# ESP32-S31 register map
Vendor: ESPRESSIF SYSTEMS (SHANGHAI) CO., LTD.; Series: ESP32 S-Series; File version: 1
CPU: RV32IMAFC r0p0, little endian, no MPU, FPU, 0 interrupt priority bits
Address unit: 32 bits
Registers are 32-bit, read-write, reset 0x0 unless marked. A register's access mark holds for its fields unless they carry their own. Offsets are from the block's base; [hi:lo] are bit positions; {n}, {i} and the like mark numbered series.

## LP_IO_MUX
Base 0x20712000
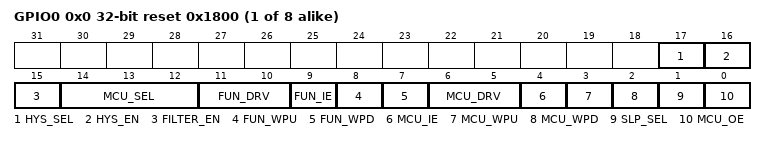
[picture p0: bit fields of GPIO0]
{0x0+4i} GPIO{i} (i=0..7) reset 0x1800
  [17] HYS_SEL, [16] HYS_EN, [15] FILTER_EN, [14:12] MCU_SEL, [11:10] FUN_DRV, [9] FUN_IE, [8] FUN_WPU, [7] FUN_WPD, [6:5] MCU_DRV, [4] MCU_IE, [3] MCU_WPU, [2] MCU_WPD, [1] SLP_SEL, [0] MCU_OE
0x1FC DATE reset 0x2201210
  [27:0] REG_DATE

## LP_TEE — Low-power Trusted Execution Environment
Base 0x20706800
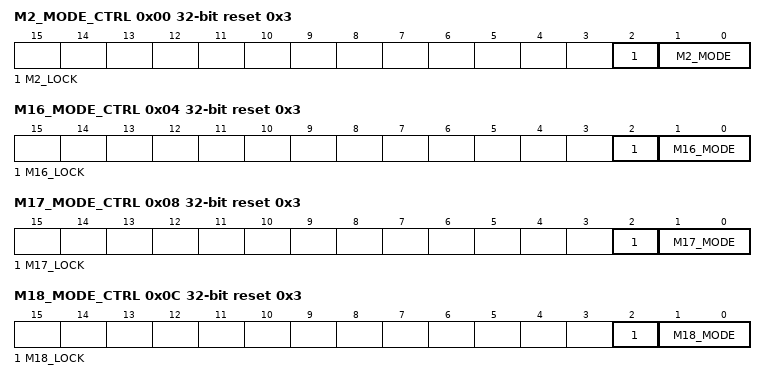
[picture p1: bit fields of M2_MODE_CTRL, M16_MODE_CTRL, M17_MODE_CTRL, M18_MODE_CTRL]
0x00 M2_MODE_CTRL reset 0x3 — TEE mode control register
  [2] M2_LOCK — Set 1 to lock m2 tee configuration
  [1:0] M2_MODE — Configures M0 security level mode.\\ 0: tee_mode \\ 1: ree_mode0 \\ 2: ree_mode1 \\ 3: ree_mode2 \\
0x04 M16_MODE_CTRL reset 0x3 — TEE mode control register
  [2] M16_LOCK — Set 1 to lock m16 tee configuration
  [1:0] M16_MODE — Configures M0 security level mode.\\ 0: tee_mode \\ 1: ree_mode0 \\ 2: ree_mode1 \\ 3: ree_mode2 \\
0x08 M17_MODE_CTRL reset 0x3 — TEE mode control register
  [2] M17_LOCK — Set 1 to lock m17 tee configuration
  [1:0] M17_MODE — Configures M0 security level mode.\\ 0: tee_mode \\ 1: ree_mode0 \\ 2: ree_mode1 \\ 3: ree_mode2 \\
0x0C M18_MODE_CTRL reset 0x3 — TEE mode control register
  [2] M18_LOCK — Set 1 to lock m18 tee configuration
  [1:0] M18_MODE — Configures M0 security level mode.\\ 0: tee_mode \\ 1: ree_mode0 \\ 2: ree_mode1 \\ 3: ree_mode2 \\
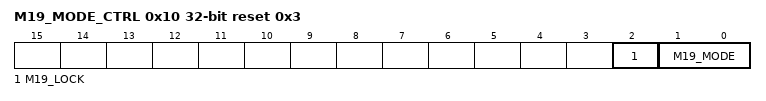
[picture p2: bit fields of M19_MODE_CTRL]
0x10 M19_MODE_CTRL reset 0x3 — TEE mode control register
  [2] M19_LOCK — Set 1 to lock m19 tee configuration
  [1:0] M19_MODE — Configures M0 security level mode.\\ 0: tee_mode \\ 1: ree_mode0 \\ 2: ree_mode1 \\ 3: ree_mode2 \\
0x14 FORCE_ACC_HP — Force access to hpmem configuration register
  [7:0] FORCE_ACC_HPMEM_EN — Configures whether to allow LP CPU to force access to HP_MEM regardless of permission management.\\ 0x5a: enable force access HP_MEM \\ other: disable force access HP_MEM \\
0x18 LP_GPIO_SECURITY — need des
  [7:0] LP_GPIO_LOCK — This field decides whether lp_gpio_config can be locked, or not. 0 (default): unlocked. 1: locked.
0x1C HP_GPIO_SECURITY_1 — need des
  [31:0] HP_GPIO_LOCK_P1 — This field decides whether hp_gpio_config of PIN0~31 can be locked, or not. 0 (default): unlocked. 1: locked.
0x20 HP_GPIO_SECURITY_2 — need des
  [30:0] HP_GPIO_LOCK_P2 — This field decides whether hp_gpio_config of PIN32~62 can be locked, or not. 0 (default): unlocked. 1: locked.
0x3F8 CLOCK_GATE reset 0x1 — Clock gating register
  [0] CLK_EN — Configures whether to keep the clock always on.\\ 0: enable automatic clock gating \\ 1: keep the clock always on \\
0x3FC DATE reset 0x2506240 — Version control register
  [27:0] DATE

## PAU — PAU Peripheral
Base 0x20341000
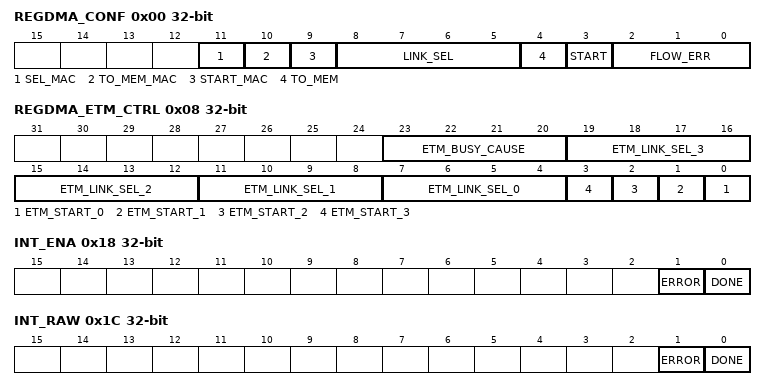
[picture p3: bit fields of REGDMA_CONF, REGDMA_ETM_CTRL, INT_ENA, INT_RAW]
0x00 REGDMA_CONF access per field — Peri backup control register
  [11] SEL_MAC rw — mac hw/sw select
  [10] TO_MEM_MAC rw — mac sw backup direction(reg to mem / mem to reg)
  [9] START_MAC wo — mac sw backup start signal
  [8:5] LINK_SEL rw — Link select
  [4] TO_MEM rw — backup direction(reg to mem / mem to reg)
  [3] START wo — backup start signal
  [2:0] FLOW_ERR ro — backup error type
0x04 REGDMA_CLK_CONF — Clock control register
  [0] CLK_EN — clock enable
0x08 REGDMA_ETM_CTRL access per field — ETM start ctrl reg
  [23:20] ETM_BUSY_CAUSE ro — debug
  [4n+7:4n+4] ETM_LINK_SEL_{n} rw (n=0..3) — etm_link sel
  [n] ETM_START_{n} wo (n=0..3) — etm_start_{n} reg
0x0C REGDMA_CURRENT_LINK_ADDR ro — current link addr
  [31:0] CURRENT_LINK_ADDR — current link addr reg
0x10 REGDMA_PERI_ADDR ro — Backup addr
  [31:0] PERI_ADDR — peri addr reg
0x14 REGDMA_MEM_ADDR ro — mem addr
  [31:0] MEM_ADDR — mem addr reg
0x18 INT_ENA — Read only register for error and done
  [1] ERROR — error flag
  [0] DONE — backup done flag
0x1C INT_RAW — Read only register for error and done
  [1] ERROR — error flag
  [0] DONE — backup done flag
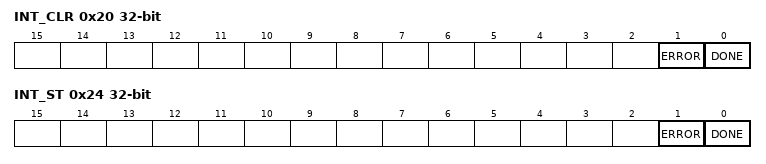
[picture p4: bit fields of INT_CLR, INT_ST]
0x20 INT_CLR wo — Read only register for error and done
  [1] ERROR write-1-clears — error flag
  [0] DONE write-1-clears — backup done flag
0x24 INT_ST ro — Read only register for error and done
  [1] ERROR — error flag
  [0] DONE — backup done flag
0x3FC DATE reset 0x2309150
  [27:0] DATE — REGDMA date information/ REGDMA version information.
